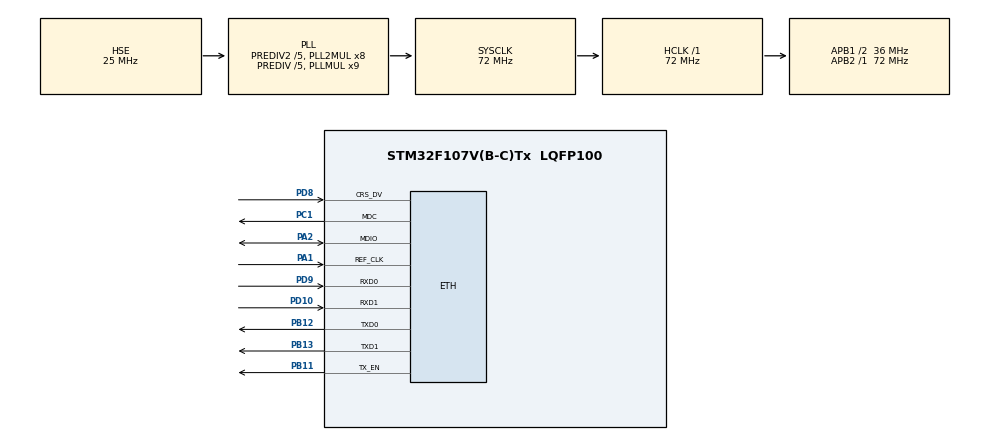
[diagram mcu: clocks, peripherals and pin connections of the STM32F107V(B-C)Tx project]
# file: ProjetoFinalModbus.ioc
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ETH.MediaInterface=ETH_MEDIA_INTERFACE_RMII
ETH.PHY_Name_RMII=DP83848_PHY_ADDRESS
ETH.RxMode=ETH_RXINTERRUPT_MODE
FREERTOS.Tasks01=defaultTask,24,128,StartDefaultTask,Default,NULL,Dynamic,NULL,NULL;modbusTask,8,128,ModbusTask,Default,NULL,Dynamic,NULL,NULL
FREERTOS.configTOTAL_HEAP_SIZE=10000
FREERTOS.configUSE_NEWLIB_REENTRANT=1
LWIP.GATEWAY_ADDRESS=192.168.001.001
LWIP.IP_ADDRESS=192.168.001.040
LWIP.LWIP_DHCP=0
LWIP.NETMASK_ADDRESS=255.255.255.000
LWIP.RTOS_USE_NEWLIB_REENTRANT=1
LWIP.Version=v2.0.3_Cube
Mcu.Family=STM32F1
Mcu.Name=STM32F107V(B-C)Tx
Mcu.Package=LQFP100
NVIC.ETH_IRQn=true\:5\:0\:false\:false\:true\:true\:true\:true\:true
NVIC.PriorityGroup=NVIC_PRIORITYGROUP_4
NVIC.TIM7_IRQn=true\:15\:0\:false\:false\:true\:false\:false\:true\:true
NVIC.TimeBase=TIM7_IRQn
NVIC.TimeBaseIP=TIM7
OSC_IN.Mode=HSE-External-Oscillator
OSC_IN.Signal=RCC_OSC_IN
OSC_OUT.Mode=HSE-External-Oscillator
OSC_OUT.Signal=RCC_OSC_OUT
PA1.Mode=RMII
PA1.Signal=ETH_REF_CLK
PA13.Mode=Trace_Asynchronous_SW
PA13.Signal=SYS_JTMS-SWDIO
PA14.Mode=Trace_Asynchronous_SW
PA14.Signal=SYS_JTCK-SWCLK
PA2.Mode=RMII
PA2.Signal=ETH_MDIO
PB11.Mode=RMII
PB11.Signal=ETH_TX_EN
PB12.Mode=RMII
PB12.Signal=ETH_TXD0
PB13.Mode=RMII
PB13.Signal=ETH_TXD1
PB3.Mode=Trace_Asynchronous_SW
PB3.Signal=SYS_TRACESWO
PC1.Mode=RMII
PC1.Signal=ETH_MDC
PD10.Mode=RMII
PD10.Signal=ETH_RXD1
PD8.Mode=RMII
PD8.Signal=ETH_CRS_DV
PD9.Mode=RMII
PD9.Signal=ETH_RXD0
ProjectManager.HeapSize=0x200
ProjectManager.StackSize=0x400
ProjectManager.TargetToolchain=STM32CubeIDE
RCC.AHBFreq_Value=72000000
RCC.APB1CLKDivider=RCC_HCLK_DIV2
RCC.APB1Freq_Value=36000000
RCC.APB1TimFreq_Value=72000000
RCC.APB2Freq_Value=72000000
RCC.APB2TimFreq_Value=72000000
RCC.HCLKFreq_Value=72000000
RCC.HSEDivPLL=RCC_HSE_PREDIV_DIV5
RCC.HSE_VALUE=25000000
RCC.PLLMUL=RCC_PLL_MUL9
RCC.PLLSourceVirtual=RCC_PLLSOURCE_HSE
RCC.Prediv1Source=RCC_PREDIV1_SOURCE_PLL2
RCC.Prediv2=RCC_HSE_PREDIV2_DIV5
RCC.SYSCLKFreq_VALUE=72000000
RCC.SYSCLKSource=RCC_SYSCLKSOURCE_PLLCLK
RCC.USBFreq_Value=48000000
VP_FREERTOS_VS_CMSIS_V2.Mode=CMSIS_V2
VP_LWIP_VS_Enabled.Mode=Enabled
VP_SYS_VS_tim7.Mode=TIM7
board=custom

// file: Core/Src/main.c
/* USER CODE BEGIN Header */
/**
  ******************************************************************************
  * @file           : main.c
  * @brief          : Main program body
  ******************************************************************************
  * @attention
  *
  * Copyright (c) 2025 STMicroelectronics.
  * All rights reserved.
  *
  * This software is licensed under terms that can be found in the LICENSE file
  * in the root directory of this software component.
  * If no LICENSE file comes with this software, it is provided AS-IS.
  *
  ******************************************************************************
  */
/* USER CODE END Header */
#include "main.h"
#include "cmsis_os.h"
#include "lwip.h"
#include "gpio.h"

void SystemClock_Config(void);
void MX_FREERTOS_Init(void);

int main(void)
{

  /* MCU Configuration--------------------------------------------------------*/

  /* Reset of all peripherals, Initializes the Flash interface and the Systick. */
  HAL_Init();

  /* Configure the system clock */
  SystemClock_Config();

  /* Initialize all configured peripherals */
  MX_GPIO_Init();

  /* Init scheduler */
  osKernelInitialize();

  /* Call init function for freertos objects (in freertos.c) */
  MX_FREERTOS_Init();

  /* Start scheduler */
  osKernelStart();

  /* We should never get here as control is now taken by the scheduler */
  /* Infinite loop */
  while (1)
  {

  }
}

void SystemClock_Config(void)
{
  RCC_OscInitTypeDef RCC_OscInitStruct = {0};
  RCC_ClkInitTypeDef RCC_ClkInitStruct = {0};

  /** Initializes the RCC Oscillators according to the specified parameters
  * in the RCC_OscInitTypeDef structure.
  */
  RCC_OscInitStruct.OscillatorType = RCC_OSCILLATORTYPE_HSE;
  RCC_OscInitStruct.HSEState = RCC_HSE_ON;
  RCC_OscInitStruct.HSEPredivValue = RCC_HSE_PREDIV_DIV5;
  RCC_OscInitStruct.HSIState = RCC_HSI_ON;
  RCC_OscInitStruct.Prediv1Source = RCC_PREDIV1_SOURCE_PLL2;
  RCC_OscInitStruct.PLL.PLLState = RCC_PLL_ON;
  RCC_OscInitStruct.PLL.PLLSource = RCC_PLLSOURCE_HSE;
  RCC_OscInitStruct.PLL.PLLMUL = RCC_PLL_MUL9;
  RCC_OscInitStruct.PLL2.PLL2State = RCC_PLL2_ON;
  RCC_OscInitStruct.PLL2.PLL2MUL = RCC_PLL2_MUL8;
  RCC_OscInitStruct.PLL2.HSEPrediv2Value = RCC_HSE_PREDIV2_DIV5;
  if (HAL_RCC_OscConfig(&RCC_OscInitStruct) != HAL_OK)
  {
    Error_Handler();
  }

  /** Initializes the CPU, AHB and APB buses clocks
  */
  RCC_ClkInitStruct.ClockType = RCC_CLOCKTYPE_HCLK|RCC_CLOCKTYPE_SYSCLK
                              |RCC_CLOCKTYPE_PCLK1|RCC_CLOCKTYPE_PCLK2;
  RCC_ClkInitStruct.SYSCLKSource = RCC_SYSCLKSOURCE_PLLCLK;
  RCC_ClkInitStruct.AHBCLKDivider = RCC_SYSCLK_DIV1;
  RCC_ClkInitStruct.APB1CLKDivider = RCC_HCLK_DIV2;
  RCC_ClkInitStruct.APB2CLKDivider = RCC_HCLK_DIV1;

  if (HAL_RCC_ClockConfig(&RCC_ClkInitStruct, FLASH_LATENCY_2) != HAL_OK)
  {
    Error_Handler();
  }

  /** Configure the Systick interrupt time
  */
  __HAL_RCC_PLLI2S_ENABLE();
}

void HAL_TIM_PeriodElapsedCallback(TIM_HandleTypeDef *htim)
{
  if (htim->Instance == TIM7) {
    HAL_IncTick();
  }
}

void Error_Handler(void)
{
  __disable_irq();
  while (1)
  {
  }
}

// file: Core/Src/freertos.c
/* USER CODE BEGIN Header */
/**
 ******************************************************************************
 * File Name          : freertos.c
 * Description        : Code for freertos applications
 ******************************************************************************
 * @attention
 *
 * Copyright (c) 2025 STMicroelectronics.
 * All rights reserved.
 *
 * This software is licensed under terms that can be found in the LICENSE file
 * in the root directory of this software component.
 * If no LICENSE file comes with this software, it is provided AS-IS.
 *
 ******************************************************************************
 */
/* USER CODE END Header */

#include "FreeRTOS.h"
#include "task.h"
#include "main.h"
#include "cmsis_os.h"

/* USER CODE BEGIN Includes */

#include "mb.h"
#include "mbtcp.h"
#include <stdio.h>
/* USER CODE END Includes */

/* Definitions for defaultTask */
osThreadId_t defaultTaskHandle;
const osThreadAttr_t defaultTask_attributes = {
  .name = "defaultTask",
  .stack_size = 128 * 4,
  .priority = (osPriority_t) osPriorityNormal,
};
/* Definitions for modbusTask */
osThreadId_t modbusTaskHandle;
const osThreadAttr_t modbusTask_attributes = {
  .name = "modbusTask",
  .stack_size = 128 * 4,
  .priority = (osPriority_t) osPriorityLow,
};

void StartDefaultTask(void *argument);
void ModbusTask(void *argument);

extern void MX_LWIP_Init(void);
void MX_FREERTOS_Init(void); /* (MISRA C 2004 rule 8.1) */

void MX_FREERTOS_Init(void) {

  /* Create the thread(s) */
  /* creation of defaultTask */
  defaultTaskHandle = osThreadNew(StartDefaultTask, NULL, &defaultTask_attributes);

  /* creation of modbusTask */
  modbusTaskHandle = osThreadNew(ModbusTask, NULL, &modbusTask_attributes);

}

void StartDefaultTask(void *argument)
{
  /* init code for LWIP */
  MX_LWIP_Init();
	for(;;)
	{
		osDelay(1);
	}
}

void ModbusTask(void *argument)
{
  /* USER CODE BEGIN ModbusTask */
	eMBErrorCode eStatus;
	/* Infinite loop */

	eStatus = eMBTCPInit(502);
	if (eStatus != MB_ENOERR)
	{
		//printf("Erro MBTCPInit: %d\n", eStatus);
		vTaskSuspend(NULL);
	}

	eMBEnable();
	for(;;)
	{
		eMBPoll();          // processa requisições Modbus
		osDelay(1);      // cede CPU ao RTOS
	}
  /* USER CODE END ModbusTask */
}
